# DPWM register map
Vendor: Texas Instruments
Peripheral module from a debugger description file (folder ucd3138128A).
Registers are 32-bit, access not given, no defined reset value unless marked. A register's access mark holds for its fields unless they carry their own. Offsets are as the file gives them; lines under a group give offsets from that group; [hi:lo] are bit positions; {n}, {i} and the like mark numbered series; 'fields as' and 'values as' point back to an identical list; <NAME> marks a mode.

## DPWM
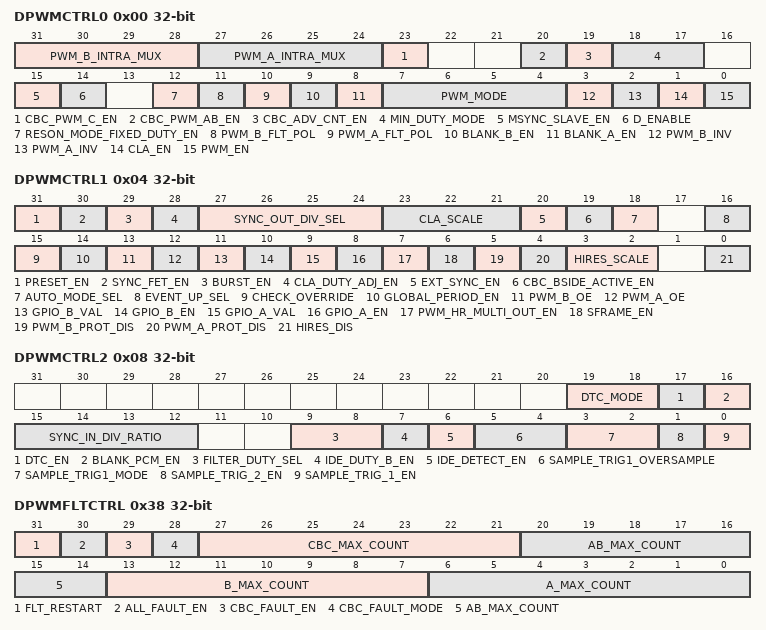
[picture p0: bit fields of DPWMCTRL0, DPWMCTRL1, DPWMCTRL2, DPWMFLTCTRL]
0x00 DPWMCTRL0
  [31:28] PWM_B_INTRA_MUX rw — PWM B Intramux Configuration
  [27:24] PWM_A_INTRA_MUX rw — PWM A Intramux Configuration
  [23] CBC_PWM_C_EN rw — Cycle-by-Cycle PWM C Enable
  [20] CBC_PWM_AB_EN rw — Cycle-by-Cycle Current Limit Mode
  [19] CBC_ADV_CNT_EN rw — Cycle-by-Cycle Current Limit Enable
  [18:17] MIN_DUTY_MODE rw — Minimum Duty Cycle Clamp Select
  [15] MSYNC_SLAVE_EN rw — Internal sync enable
  [14] D_ENABLE rw — 1-D Enable
  [12] RESON_MODE_FIXED_DUTY_EN rw — Controls Pulse Width in Resonance Mode
  [11] PWM_B_FLT_POL rw — PWM B Fault Polarity
  [10] PWM_A_FLT_POL rw — PWM A Fault Polarity
  [9] BLANK_B_EN rw — PWM B Comparator Blanking Enable
  [8] BLANK_A_EN rw — PWM A Comparator Blanking Enable
  [7:4] PWM_MODE rw — Configures DPWM mode of operation
  [3] PWM_B_INV rw — PWM B polarity inversion
  [2] PWM_A_INV rw — PWM A polarity inversion
  [1] CLA_EN rw — PWM input selection - enable CLA input
  [0] PWM_EN rw — PWM enable
0x04 DPWMCTRL1
  [31] PRESET_EN rw — Preset Counter Enable
  [30] SYNC_FET_EN rw — SyncFET Mode Enable
  [29] BURST_EN rw — Burst (Light Load) Mode enable
  [28] CLA_DUTY_ADJ_EN rw — Current/Flux Balancing Adjustment Enable
  [27:24] SYNC_OUT_DIV_SEL rw — Sync out divider select
  [23:21] CLA_SCALE rw — CLA scaling select
  [20] EXT_SYNC_EN rw — Slave DPWM to external sync
  [19] CBC_BSIDE_ACTIVE_EN rw — Cycle-by-Cycle B Side Active Enable
  [18] AUTO_MODE_SEL rw — Auto Mode Switching Select
  [16] EVENT_UP_SEL rw — PWM Update mode
  [15] CHECK_OVERRIDE rw — Override PWM checks for invalid config
  [14] GLOBAL_PERIOD_EN rw — PWM Global Period Enable
  [13] PWM_B_OE rw — PWM B output enable
  [12] PWM_A_OE rw — PWM A output enable
  [11] GPIO_B_VAL rw — PWM B output in GPIO mode
  [10] GPIO_B_EN rw — PWM B output enable in GPIO mode
  [9] GPIO_A_VAL rw — PWM A output in GPIO mode
  [8] GPIO_A_EN rw — PWM A output enable in GPIO mode
  [7] PWM_HR_MULTI_OUT_EN rw — PWM High Res Multi-Mode Output Enable
  [6] SFRAME_EN rw — PWM single frame mode select
  [5] PWM_B_PROT_DIS rw — PWM B async protection disable
  [4] PWM_A_PROT_DIS rw — PWM A async protection disable
  [3:2] HIRES_SCALE rw — Hi-resolution scale select
  [0] HIRES_DIS rw — Hi-resolution disable
0x08 DPWMCTRL2
  [19:18] DTC_MODE rw — DTC Mode Selector
  [17] DTC_EN rw — DTC Enable
  [16] BLANK_PCM_EN rw — Blanking Mask PCM Enable
  [15:12] SYNC_IN_DIV_RATIO rw — External Sync In Divide Ratio
  [9:8] FILTER_DUTY_SEL rw — Selects DPWM Duty for Mode Switching
  [7] IDE_DUTY_B_EN rw — IDE Duty Cycle Side B Enable
  [6] IDE_DETECT_EN rw — IDE Detect Enable
  [5:4] SAMPLE_TRIG1_OVERSAMPLE rw — Configures Oversampling function
  [3:2] SAMPLE_TRIG1_MODE rw — Sample Trigger Configuration
  [1] SAMPLE_TRIG_2_EN rw — Sample Trigger 2 Enable
  [0] SAMPLE_TRIG_1_EN rw — Sample Trigger 1 Enable
0x0C DPWMPRD
  [17:4] PRD ro — PWM Period - clock periods + 1
0x10 DPWMEV1
  [17:4] EVENT1 rw — Event 1 configuration
{0xC+4i} DPWMEV{i} (i=2..4)
  [17:0] EVENT{i} rw — Event {i} configuration
0x20 DPWMSAMPTRIG1
  [17:6] SAMPLE_TRIGGER rw — Sample trigger configuration
0x24 DPWMSAMPTRIG2
  [17:6] SAMPLE_TRIGGER rw — Sample trigger configuration
0x28 DPWMPHASETRIG
  [17:4] PHASE_TRIGGER rw — Phase trigger configuration
0x2C DPWMCYCADJA
  [15:0] CYCLE_ADJUST_A rw
0x30 DPWMCYCADJB
  [15:0] CYCLE_ADJUST_B rw
0x34 DPWMRESDUTY
  [13:0] RESONANT_DUTY rw — Resonant Duty Adjust
0x38 DPWMFLTCTRL rw
  [31] FLT_RESTART — Fault Restart
  [30] ALL_FAULT_EN — Fault Module Enable
  [29] CBC_FAULT_EN — CBC Fault Module Enable
  [28] CBC_FAULT_MODE — CBC Fault Mode Select
  [27:21] CBC_MAX_COUNT — Cycle-by-Cycle Max Count
  [20:14] AB_MAX_COUNT — Fault AB Cycle Max Count
  [13:7] B_MAX_COUNT — Fault B Cycle Max Count
  [6:0] A_MAX_COUNT — Fault A Cycle Max Count
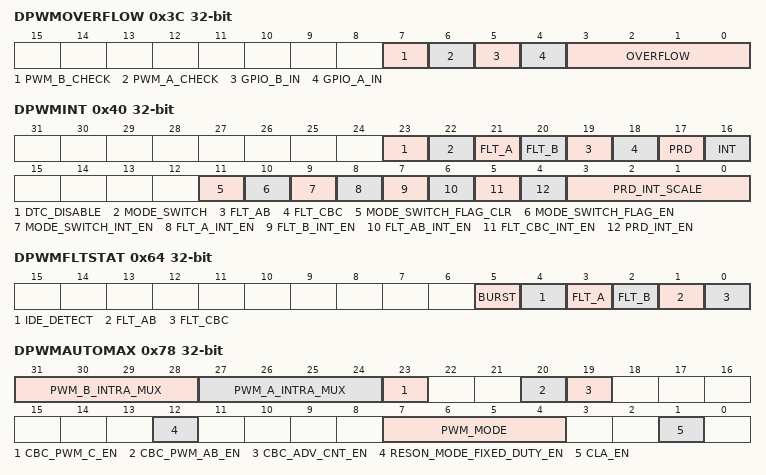
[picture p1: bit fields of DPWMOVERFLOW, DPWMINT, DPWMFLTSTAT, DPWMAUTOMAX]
0x3C DPWMOVERFLOW
  [7] PWM_B_CHECK ro — Value of PWM B Internal Check
  [6] PWM_A_CHECK ro — Value of PWM A Internal Check
  [5] GPIO_B_IN ro — Input value of PWM B
  [4] GPIO_A_IN ro — Input value of PWM A
  [3:0] OVERFLOW ro — DPWM Overflow status
0x40 DPWMINT
  [23] DTC_DISABLE ro — DTC Disabled Flag
  [22] MODE_SWITCH ro — Mode Switching Flag
  [21] FLT_A ro — Fault A Flag
  [20] FLT_B ro — Fault B Flag
  [19] FLT_AB ro — Fault AB Flag
  [18] FLT_CBC ro — Fault CBC Flag
  [17] PRD ro — PWM Period Interrupt Flag
  [16] INT ro — Interrupt Status
  [11] MODE_SWITCH_FLAG_CLR rw — Mode Switching Flag Clear
  [10] MODE_SWITCH_FLAG_EN rw — Mode Switching Flag Enable
  [9] MODE_SWITCH_INT_EN rw — Mode Switching Interrupt Enable
  [8] FLT_A_INT_EN rw — Fault A Interrupt Enable
  [7] FLT_B_INT_EN rw — Fault B Interrupt Enable
  [6] FLT_AB_INT_EN rw — Fault AB Interrupt Enable
  [5] FLT_CBC_INT_EN rw — Fault CBC Interrupt Enable
  [4] PRD_INT_EN rw — End-of-Period Interrupt Enable
  [3:0] PRD_INT_SCALE rw — End-of-Period Interrupt Scale
0x44 DPWMCNTPRE
  [17:4] PRESET rw — Preset DPWM Counter value
0x48 DPWMBLKABEG
  [17:4] BLANK_A_BEGIN rw — Start of PWM A Comparator Blanking
0x4C DPWMBLKAEND
  [17:4] BLANK_A_END rw — End of PWM A Comparator Blanking
0x50 DPWMBLKBBEG
  [17:4] BLANK_B_BEGIN rw — Start of PWM B Comparator Blanking
0x54 DPWMBLKBEND
  [17:4] BLANK_B_END rw — End of PWM B Comparator Blanking
0x58 DPWMMINDUTYHI
  [17:4] MIN_DUTY_HIGH rw — Minimum Duty High Threshold
0x5C DPWMMINDUTYLO
  [17:4] MIN_DUTY_LOW rw — Minimum Duty Low Threshold
0x60 DPWMADAPTIVE
  [11:0] ADAPT_SAMP rw — Adaptive Sample Adjust
0x64 DPWMFLTSTAT
  [5] BURST ro — Burst Mode
  [4] IDE_DETECT ro — IDE Detect Indication
  [3] FLT_A ro — Fault A Detection
  [2] FLT_B ro — Fault B Detection
  [1] FLT_AB ro — Fault AB Detection
  [0] FLT_CBC ro — Current Limit Detection
0x68 DPWMAUTOSWHIUPTHRESH
  [17:4] AUTO_SWITCH_HIGH_UPPER rw — Auto Switch High Threshold
0x6C DPWMAUTOSWHILOWTHRESH
  [17:4] AUTO_SWITCH_HIGH_LOWER rw — Auto Switch High Threshold
0x70 DPWMAUTOSWLOUPTHRESH
  [17:4] AUTO_SWITCH_LOW_UPPER rw — Auto Switch Low Threshold
0x74 DPWMAUTOSWLOLOWTHRESH
  [17:4] AUTO_SWITCH_LOW_LOWER rw — Auto Switch Low Threshold
0x78 DPWMAUTOMAX
  [31:28] PWM_B_INTRA_MUX rw — PWM B Intramux Configuration
  [27:24] PWM_A_INTRA_MUX rw — PWM A Intramux Configuration
  [23] CBC_PWM_C_EN rw — Cycle-by-Cycle PWM C Enable
  [20] CBC_PWM_AB_EN rw — Cycle-by-Cycle Current Limit Mode
  [19] CBC_ADV_CNT_EN rw — Cycle-by-Cycle Current Limit Enable
  [12] RESON_MODE_FIXED_DUTY_EN rw — Controls Pulse Width in Resonance Mode
  [7:4] PWM_MODE rw — Configures DPWM mode of operation
  [1] CLA_EN rw — PWM input selection - enable CLA input
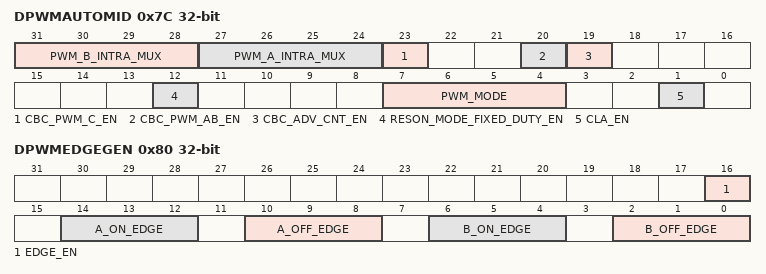
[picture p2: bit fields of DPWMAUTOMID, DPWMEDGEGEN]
0x7C DPWMAUTOMID
  fields as DPWMAUTOMAX
0x80 DPWMEDGEGEN
  [16] EDGE_EN rw — Enables Edge Generate Module
  [14:12] A_ON_EDGE rw — A On Edge Trigger Select
  [10:8] A_OFF_EDGE rw — A Off Edge Trigger Select
  [6:4] B_ON_EDGE rw — B On Edge Trigger Select
  [2:0] B_OFF_EDGE rw — B Off Edge Trigger Select
0x84 DPWMFILTERDUTYREAD
  [17:0] FILTER_DUTY ro
0x88 DPWMCBCLOCATION
  [13:0] CBC_LOCATION ro
